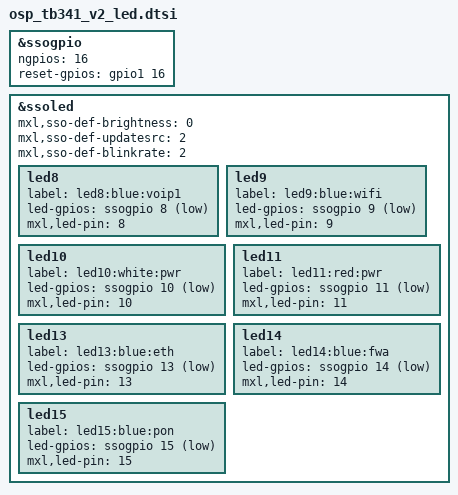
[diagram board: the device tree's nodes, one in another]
// SPDX-License-Identifier: GPL-2.0
/*
 * Copyright (C) 2023 MaxLinear, Inc.
 */

&ssogpio {
	status = "okay";
	ngpios = <16>;
	reset-gpios = <&gpio1 16 GPIO_ACTIVE_HIGH>;
};

&ssoled {
	status = "okay";
	mxl,sso-def-brightness = <0>;
	mxl,sso-def-updatesrc = <2>; /* 0 - manual, 1 - gptc 2 - fpid */
	mxl,sso-def-blinkrate = <2>;

	led8: led8 { /* VOIP1_B */
		label = "led8:blue:voip1";
		led-gpios = <&ssogpio 8 GPIO_ACTIVE_LOW>;
		mxl,led-pin = <8>;
	};

	led9: led9 { /* WIFI_B */
		label = "led9:blue:wifi";
		led-gpios = <&ssogpio 9 GPIO_ACTIVE_LOW>;
		mxl,led-pin = <9>;
	};

	led10: led10 { /* PWR_W */
		label = "led10:white:pwr";
		led-gpios = <&ssogpio 10 GPIO_ACTIVE_LOW>;
		mxl,led-pin = <10>;
	};

	led11: led11 { /* PWR_R */
		label = "led11:red:pwr";
		led-gpios = <&ssogpio 11 GPIO_ACTIVE_LOW>;
		mxl,led-pin = <11>;
	};

	led13: led13 { /* ETH_B */
		label = "led13:blue:eth";
		led-gpios = <&ssogpio 13 GPIO_ACTIVE_LOW>;
		mxl,led-pin = <13>;
	};

	led14: led14 { /* FWA_B */
		label = "led14:blue:fwa";
		led-gpios = <&ssogpio 14 GPIO_ACTIVE_LOW>;
		mxl,led-pin = <14>;
	};

	led15: led15 { /* PON_B */
		label = "led15:blue:pon";
		led-gpios = <&ssogpio 15 GPIO_ACTIVE_LOW>;
		mxl,led-pin = <15>;
	};
};
